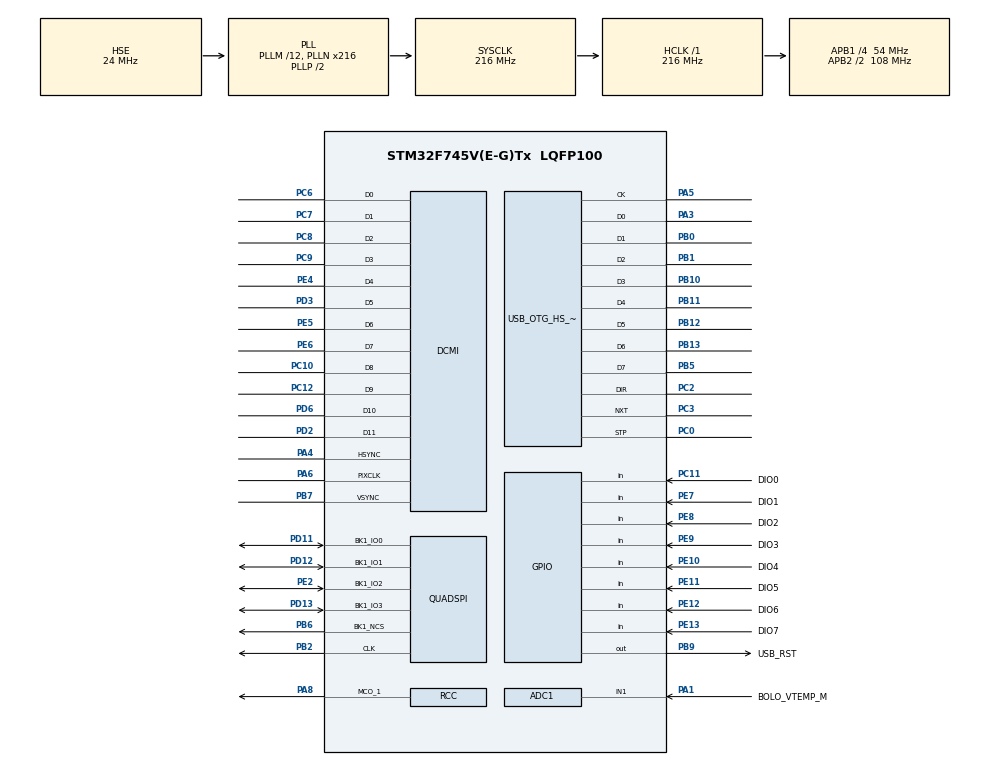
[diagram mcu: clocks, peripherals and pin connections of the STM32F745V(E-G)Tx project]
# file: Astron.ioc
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ADC1.Channel-0\#ChannelRegularConversion=ADC_CHANNEL_1
ADC1.NbrOfConversionFlag=1
ADC1.Rank-0\#ChannelRegularConversion=1
ADC1.SamplingTime-0\#ChannelRegularConversion=ADC_SAMPLETIME_3CYCLES
ADC1.master=1
Mcu.Family=STM32F7
Mcu.Name=STM32F745V(E-G)Tx
Mcu.Package=LQFP100
NVIC.OTG_HS_IRQn=true\:0\:0\:false\:false\:true\:false\:true
NVIC.PriorityGroup=NVIC_PRIORITYGROUP_4
PA1.GPIO_Label=BOLO_VTEMP_M
PA1.Signal=ADCx_IN1
PA13.Mode=Serial_Wire
PA13.Signal=SYS_JTMS-SWDIO
PA14.Mode=Serial_Wire
PA14.Signal=SYS_JTCK-SWCLK
PA3.Mode=Device_HS
PA3.Signal=USB_OTG_HS_ULPI_D0
PA4.Mode=Slave_12_bits_External_Synchro
PA4.Signal=DCMI_HSYNC
PA5.Mode=Device_HS
PA5.Signal=USB_OTG_HS_ULPI_CK
PA6.Mode=Slave_12_bits_External_Synchro
PA6.Signal=DCMI_PIXCLK
PA8.Mode=Clock-out-1
PA8.Signal=RCC_MCO_1
PB0.Mode=Device_HS
PB0.Signal=USB_OTG_HS_ULPI_D1
PB1.Mode=Device_HS
PB1.Signal=USB_OTG_HS_ULPI_D2
PB10.Mode=Device_HS
PB10.Signal=USB_OTG_HS_ULPI_D3
PB11.Mode=Device_HS
PB11.Signal=USB_OTG_HS_ULPI_D4
PB12.Mode=Device_HS
PB12.Signal=USB_OTG_HS_ULPI_D5
PB13.Mode=Device_HS
PB13.Signal=USB_OTG_HS_ULPI_D6
PB2.Mode=Single Bank 1
PB2.Signal=QUADSPI_CLK
PB5.Mode=Device_HS
PB5.Signal=USB_OTG_HS_ULPI_D7
PB6.Mode=Single Bank 1
PB6.Signal=QUADSPI_BK1_NCS
PB7.Mode=Slave_12_bits_External_Synchro
PB7.Signal=DCMI_VSYNC
PB9.GPIO_Label=USB_RST
PB9.Signal=GPIO_Output
PC0.GPIO_PuPd=GPIO_PULLDOWN
PC0.Mode=Device_HS
PC0.Signal=USB_OTG_HS_ULPI_STP
PC10.Mode=Slave_12_bits_External_Synchro
PC10.Signal=DCMI_D8
PC11.GPIO_Label=DIO0
PC11.GPIO_PuPd=GPIO_PULLUP
PC11.Signal=GPIO_Input
PC12.Mode=Slave_12_bits_External_Synchro
PC12.Signal=DCMI_D9
PC2.GPIO_PuPd=GPIO_PULLDOWN
PC2.Mode=Device_HS
PC2.Signal=USB_OTG_HS_ULPI_DIR
PC3.GPIO_PuPd=GPIO_PULLDOWN
PC3.Mode=Device_HS
PC3.Signal=USB_OTG_HS_ULPI_NXT
PC6.Mode=Slave_12_bits_External_Synchro
PC6.Signal=DCMI_D0
PC7.Mode=Slave_12_bits_External_Synchro
PC7.Signal=DCMI_D1
PC8.Mode=Slave_12_bits_External_Synchro
PC8.Signal=DCMI_D2
PC9.Mode=Slave_12_bits_External_Synchro
PC9.Signal=DCMI_D3
PD11.Mode=Single Bank 1
PD11.Signal=QUADSPI_BK1_IO0
PD12.Mode=Single Bank 1
PD12.Signal=QUADSPI_BK1_IO1
PD13.Mode=Single Bank 1
PD13.Signal=QUADSPI_BK1_IO3
PD2.Mode=Slave_12_bits_External_Synchro
PD2.Signal=DCMI_D11
PD3.Mode=Slave_12_bits_External_Synchro
PD3.Signal=DCMI_D5
PD6.Mode=Slave_12_bits_External_Synchro
PD6.Signal=DCMI_D10
PE10.GPIO_Label=DIO4
PE10.GPIO_PuPd=GPIO_PULLUP
PE10.Signal=GPIO_Input
PE11.GPIO_Label=DIO5
PE11.GPIO_PuPd=GPIO_PULLUP
PE11.Signal=GPIO_Input
PE12.GPIO_Label=DIO6
PE12.GPIO_PuPd=GPIO_PULLUP
PE12.Signal=GPIO_Input
PE13.GPIO_Label=DIO7
PE13.GPIO_PuPd=GPIO_PULLUP
PE13.Signal=GPIO_Input
PE2.Mode=Single Bank 1
PE2.Signal=QUADSPI_BK1_IO2
PE4.Mode=Slave_12_bits_External_Synchro
PE4.Signal=DCMI_D4
PE5.Mode=Slave_12_bits_External_Synchro
PE5.Signal=DCMI_D6
PE6.Mode=Slave_12_bits_External_Synchro
PE6.Signal=DCMI_D7
PE7.GPIO_Label=DIO1
PE7.GPIO_PuPd=GPIO_PULLUP
PE7.Signal=GPIO_Input
PE8.GPIO_Label=DIO2
PE8.GPIO_PuPd=GPIO_PULLUP
PE8.Signal=GPIO_Input
PE9.GPIO_Label=DIO3
PE9.GPIO_PuPd=GPIO_PULLUP
PE9.Signal=GPIO_Input
PH0/OSC_IN.Mode=HSE-External-Oscillator
PH0/OSC_IN.Signal=RCC_OSC_IN
PH1/OSC_OUT.Mode=HSE-External-Oscillator
PH1/OSC_OUT.Signal=RCC_OSC_OUT
ProjectManager.HeapSize=0x2000
ProjectManager.StackSize=0x1000
ProjectManager.TargetToolchain=EWARM V8.32
RCC.AHBFreq_Value=216000000
RCC.APB1CLKDivider=RCC_HCLK_DIV4
RCC.APB1Freq_Value=54000000
RCC.APB1TimFreq_Value=108000000
RCC.APB2CLKDivider=RCC_HCLK_DIV2
RCC.APB2Freq_Value=108000000
RCC.APB2TimFreq_Value=216000000
RCC.CortexFreq_Value=216000000
RCC.HCLKFreq_Value=216000000
RCC.HSE_VALUE=24000000
RCC.HSI_VALUE=16000000
RCC.LSE_VALUE=32768
RCC.PLLM=12
RCC.PLLN=216
RCC.PLLSourceVirtual=RCC_PLLSOURCE_HSE
RCC.RCC_MCO1Source=RCC_MCO1SOURCE_HSE
RCC.SYSCLKFreq_VALUE=216000000
RCC.SYSCLKSource=RCC_SYSCLKSOURCE_PLLCLK
RCC.USBFreq_Value=216000000
RCC.VCOOutputFreq_Value=432000000
SH.ADCx_IN1.0=ADC1_IN1,IN1
USB_DEVICE.APP_RX_DATA_SIZE-CDC_HS=256
USB_DEVICE.APP_TX_DATA_SIZE-CDC_HS=256
USB_DEVICE.CLASS_NAME_HS=CDC
USB_DEVICE.VirtualMode-CDC_HS=Cdc
USB_DEVICE.VirtualModeHS=Cdc_HS
USB_OTG_HS.DeviceSpeed-Device_HS=PCD_SPEED_HIGH
USB_OTG_HS.VirtualMode-Device_HS=Device_HS
USB_OTG_HS.dma_enable-Device_HS=ENABLE
VP_USB_DEVICE_VS_USB_DEVICE_CDC_HS.Mode=CDC_HS
board=custom

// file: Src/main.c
/* USER CODE BEGIN Header */
/**
  ******************************************************************************
  * @file           : main.c
  * @brief          : Main program body
  ******************************************************************************
  * @attention
  *
  * <h2><center>&copy; Copyright (c) 2020 STMicroelectronics.
  * All rights reserved.</center></h2>
  *
  * This software component is licensed by ST under BSD 3-Clause license,
  * the "License"; You may not use this file except in compliance with the
  * License. You may obtain a copy of the License at:
  *                        opensource.org/licenses/BSD-3-Clause
  *
  ******************************************************************************
  */
/* USER CODE END Header */

#include "main.h"
#include "adc.h"
#include "dcmi.h"
#include "quadspi.h"
#include "usb_device.h"
#include "gpio.h"

void SystemClock_Config(void);

int main(void)
{

  /* MCU Configuration--------------------------------------------------------*/

  /* Reset of all peripherals, Initializes the Flash interface and the Systick. */
  HAL_Init();

  /* Configure the system clock */
  SystemClock_Config();

  /* Initialize all configured peripherals */
  MX_GPIO_Init();
  MX_ADC1_Init();
  MX_DCMI_Init();
  MX_QUADSPI_Init();
  MX_USB_DEVICE_Init();

  /* Infinite loop */
  /* USER CODE BEGIN WHILE */
  while (1)
  {
//    HAL_Delay( 1000 );
//
//    MX_USB_DEVICE_Init();

    /* USER CODE END WHILE */

  }
}

void SystemClock_Config(void)
{
  RCC_OscInitTypeDef RCC_OscInitStruct = {0};
  RCC_ClkInitTypeDef RCC_ClkInitStruct = {0};

  /** Configure the main internal regulator output voltage
  */
  __HAL_RCC_PWR_CLK_ENABLE();
  __HAL_PWR_VOLTAGESCALING_CONFIG(PWR_REGULATOR_VOLTAGE_SCALE1);
  /** Initializes the CPU, AHB and APB busses clocks
  */
  RCC_OscInitStruct.OscillatorType = RCC_OSCILLATORTYPE_HSE;
  RCC_OscInitStruct.HSEState = RCC_HSE_ON;
  RCC_OscInitStruct.PLL.PLLState = RCC_PLL_ON;
  RCC_OscInitStruct.PLL.PLLSource = RCC_PLLSOURCE_HSE;
  RCC_OscInitStruct.PLL.PLLM = 12;
  RCC_OscInitStruct.PLL.PLLN = 216;
  RCC_OscInitStruct.PLL.PLLP = RCC_PLLP_DIV2;
  RCC_OscInitStruct.PLL.PLLQ = 2;
  if (HAL_RCC_OscConfig(&RCC_OscInitStruct) != HAL_OK)
  {
    Error_Handler();
  }
  /** Activate the Over-Drive mode
  */
  if (HAL_PWREx_EnableOverDrive() != HAL_OK)
  {
    Error_Handler();
  }
  /** Initializes the CPU, AHB and APB busses clocks
  */
  RCC_ClkInitStruct.ClockType = RCC_CLOCKTYPE_HCLK|RCC_CLOCKTYPE_SYSCLK
                              |RCC_CLOCKTYPE_PCLK1|RCC_CLOCKTYPE_PCLK2;
  RCC_ClkInitStruct.SYSCLKSource = RCC_SYSCLKSOURCE_PLLCLK;
  RCC_ClkInitStruct.AHBCLKDivider = RCC_SYSCLK_DIV1;
  RCC_ClkInitStruct.APB1CLKDivider = RCC_HCLK_DIV4;
  RCC_ClkInitStruct.APB2CLKDivider = RCC_HCLK_DIV2;

  if (HAL_RCC_ClockConfig(&RCC_ClkInitStruct, FLASH_LATENCY_7) != HAL_OK)
  {
    Error_Handler();
  }
  HAL_RCC_MCOConfig(RCC_MCO1, RCC_MCO1SOURCE_HSE, RCC_MCODIV_1);
}

void Error_Handler(void)
{
}

/************************ (C) COPYRIGHT STMicroelectronics *****END OF FILE****/
